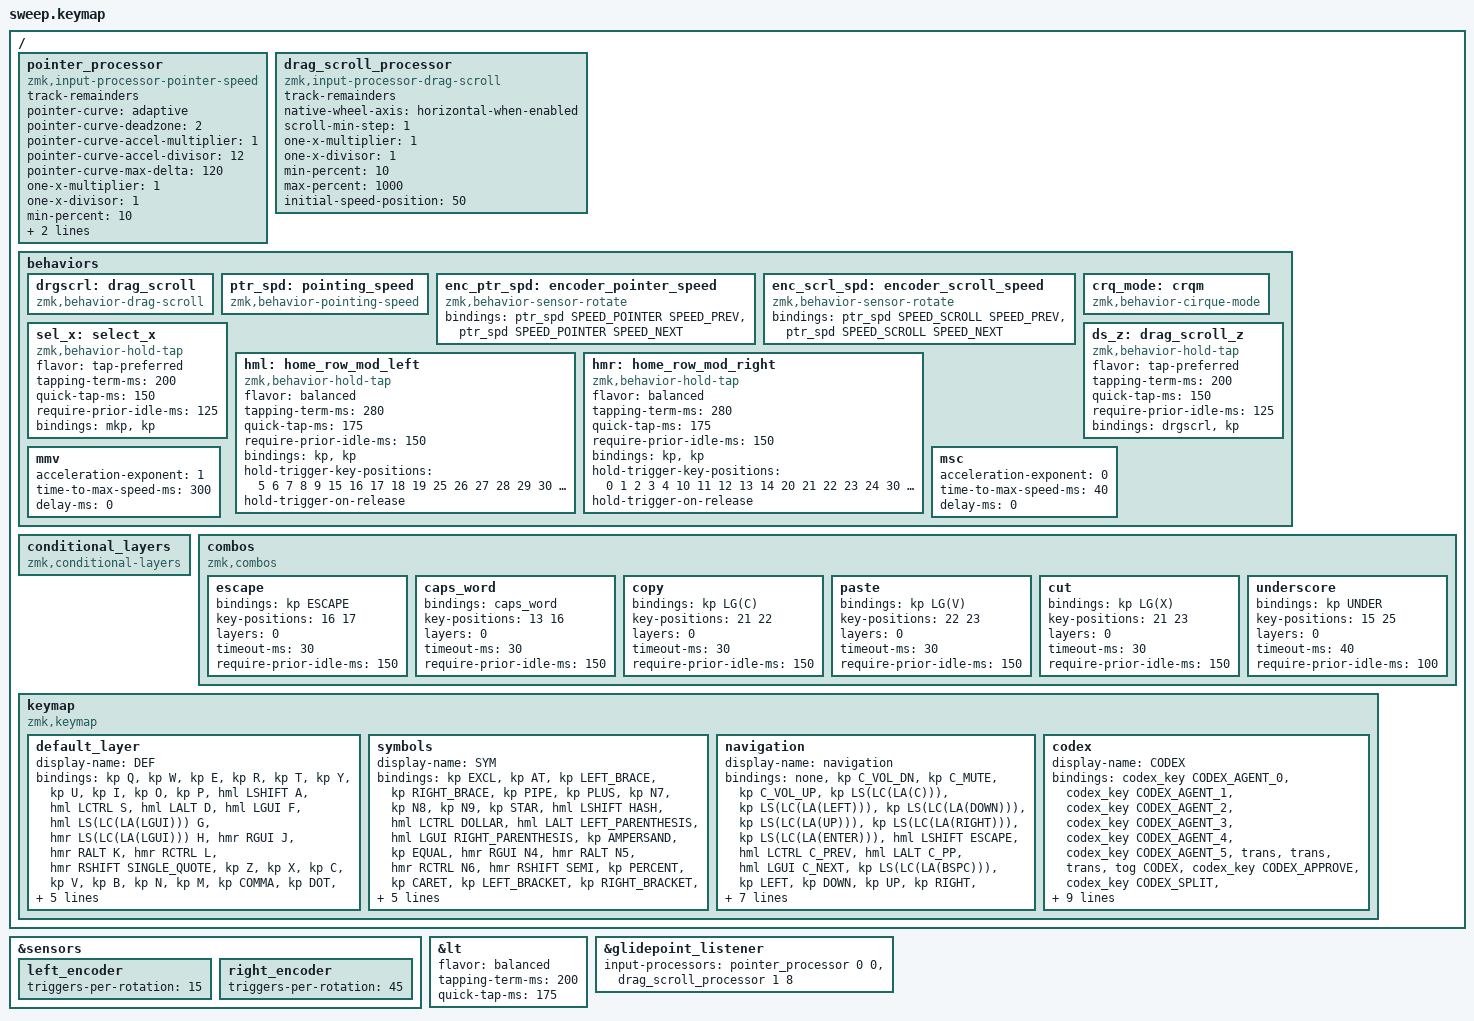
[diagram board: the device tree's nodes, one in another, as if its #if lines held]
// Copyright (c) 2022 The ZMK Contributors
// SPDX-License-Identifier: MIT
// #include <dt-bindings/zmk/rgb.h>

#define ZMK_POINTING_DEFAULT_MOVE_VAL 2500// 600
#define ZMK_POINTING_DEFAULT_SCRL_VAL 20// 10

#include <behaviors.dtsi>
#include <dt-bindings/zmk/keys.h>
#include <dt-bindings/zmk/pointing.h>

#if defined(NXTKB_CODEX_MICRO)
#include <dt-bindings/nxtkb/codex.h>
#include <behaviors/codex_key.dtsi>
#endif

#include "behaviors/character_map.dtsi"
#include "behaviors/report.dtsi"

#define MAC 0
#define WIN 1
#define RIG 2
#define LEF 3
#define TRI 4
#define MOUSE 5
#define CODEX 3
#define SPEED_POINTER 0
#define SPEED_SCROLL 1
#define SPEED_PREV 0
#define SPEED_NEXT 1
#define SPEED_RESET 2
#define SPEED_FINE_PREV 3
#define SPEED_FINE_NEXT 4
#define CIRQUE_MODE_RELATIVE 0
#define CIRQUE_MODE_ABSOLUTE 1
#define CIRQUE_MODE_TOGGLE 2

&sensors {
    left_encoder { triggers-per-rotation = <15>; };

    right_encoder { triggers-per-rotation = <45>; };
};

&lt {
    flavor = "balanced";
    tapping-term-ms = <200>;
    quick-tap-ms = <175>;
};

&glidepoint_listener { input-processors = <&pointer_processor 0 0 &drag_scroll_processor 1 8>; };

/ {
    pointer_processor: pointer_processor {
        compatible = "zmk,input-processor-pointer-speed";
        #input-processor-cells = <2>;
        track-remainders;
        pointer-curve = "adaptive";
        pointer-curve-deadzone = <2>;
        pointer-curve-accel-multiplier = <1>;
        pointer-curve-accel-divisor = <12>;
        pointer-curve-max-delta = <120>;
        one-x-multiplier = <1>;
        one-x-divisor = <1>;
        min-percent = <10>;
        max-percent = <400>;
        initial-speed-position = <50>;
    };

    drag_scroll_processor: drag_scroll_processor {
        compatible = "zmk,input-processor-drag-scroll";
        #input-processor-cells = <2>;
        track-remainders;
        native-wheel-axis = "horizontal-when-enabled";
        scroll-min-step = <1>;
        one-x-multiplier = <1>;
        one-x-divisor = <1>;
        min-percent = <10>;
        max-percent = <1000>;
        initial-speed-position = <50>;
    };

    behaviors {
        drgscrl: drag_scroll {
            compatible = "zmk,behavior-drag-scroll";
            #binding-cells = <0>;
        };

        ptr_spd: pointing_speed {
            compatible = "zmk,behavior-pointing-speed";
            #binding-cells = <2>;
        };

        enc_ptr_spd: encoder_pointer_speed {
            compatible = "zmk,behavior-sensor-rotate";
            #sensor-binding-cells = <0>;
            bindings =
                <&ptr_spd SPEED_POINTER SPEED_PREV>,
                <&ptr_spd SPEED_POINTER SPEED_NEXT>;
        };

        enc_scrl_spd: encoder_scroll_speed {
            compatible = "zmk,behavior-sensor-rotate";
            #sensor-binding-cells = <0>;
            bindings =
                <&ptr_spd SPEED_SCROLL SPEED_PREV>,
                <&ptr_spd SPEED_SCROLL SPEED_NEXT>;
        };

        crq_mode: crqm {
            compatible = "zmk,behavior-cirque-mode";
            #binding-cells = <1>;
        };

        sel_x: select_x {
            compatible = "zmk,behavior-hold-tap";
            #binding-cells = <2>;
            flavor = "tap-preferred";
            tapping-term-ms = <200>;
            quick-tap-ms = <150>;
            require-prior-idle-ms = <125>;
            bindings = <&mkp>, <&kp>;
        };

        ds_z: drag_scroll_z {
            compatible = "zmk,behavior-hold-tap";
            #binding-cells = <2>;
            flavor = "tap-preferred";
            tapping-term-ms = <200>;
            quick-tap-ms = <150>;
            require-prior-idle-ms = <125>;
            bindings = <&drgscrl>, <&kp>;
        };

        // Timeless positional home row mods (urob-style): balanced +
        // require-prior-idle + cross-hand-only trigger positions.
        // Left: 0-4 10-14 20-24, right: 5-9 15-19 25-29, thumbs: 30-35.

        hml: home_row_mod_left {
            compatible = "zmk,behavior-hold-tap";
            #binding-cells = <2>;
            flavor = "balanced";
            tapping-term-ms = <280>;
            quick-tap-ms = <175>;
            require-prior-idle-ms = <150>;
            bindings = <&kp>, <&kp>;

            hold-trigger-key-positions = <5 6 7 8 9 15 16 17 18 19 25 26 27 28 29 30 31 32 33 34 35>;
            hold-trigger-on-release;
        };

        hmr: home_row_mod_right {
            compatible = "zmk,behavior-hold-tap";
            #binding-cells = <2>;
            flavor = "balanced";
            tapping-term-ms = <280>;
            quick-tap-ms = <175>;
            require-prior-idle-ms = <150>;
            bindings = <&kp>, <&kp>;

            hold-trigger-key-positions = <0 1 2 3 4 10 11 12 13 14 20 21 22 23 24 30 31 32 33 34 35>;
            hold-trigger-on-release;
        };

        mmv {
            acceleration-exponent = <1>;// 1
            time-to-max-speed-ms = <300>;// 40
            delay-ms = <0>;// 0
        };

        msc {
            acceleration-exponent = <0>;// 0
            time-to-max-speed-ms = <40>;// 500
            delay-ms = <0>;// 10
        };
    };

    conditional_layers { compatible = "zmk,conditional-layers"; };

    combos {
        compatible = "zmk,combos";

        escape {
            bindings = <&kp ESCAPE>;
            key-positions = <16 17>;        // J + K
            layers = <0>;
            timeout-ms = <30>;
            require-prior-idle-ms = <150>;
        };

        caps_word {
            bindings = <&caps_word>;
            key-positions = <13 16>;        // F + J
            layers = <0>;
            timeout-ms = <30>;
            require-prior-idle-ms = <150>;
        };

        copy {
            bindings = <&kp LG(C)>;
            key-positions = <21 22>;        // X + C
            layers = <0>;
            timeout-ms = <30>;
            require-prior-idle-ms = <150>;
        };

        paste {
            bindings = <&kp LG(V)>;
            key-positions = <22 23>;        // C + V
            layers = <0>;
            timeout-ms = <30>;
            require-prior-idle-ms = <150>;
        };

        cut {
            bindings = <&kp LG(X)>;
            key-positions = <21 23>;        // X + V
            layers = <0>;
            timeout-ms = <30>;
            require-prior-idle-ms = <150>;
        };

        underscore {
            bindings = <&kp UNDER>;
            key-positions = <15 25>;        // H + N
            layers = <0>;
            timeout-ms = <40>;
            require-prior-idle-ms = <100>;
        };
    };

    keymap {
        compatible = "zmk,keymap";

        default_layer {
            display-name = "DEF";
            bindings = <
&kp Q          &kp W         &kp E        &kp R                     &kp T                     &kp Y                     &kp U        &kp I        &kp O         &kp P
&hml LSHIFT A  &hml LCTRL S  &hml LALT D  &hml LGUI F               &hml LS(LC(LA(LGUI))) G   &hmr LS(LC(LA(LGUI))) H   &hmr RGUI J  &hmr RALT K  &hmr RCTRL L  &hmr RSHIFT SINGLE_QUOTE
&kp Z          &kp X         &kp C        &kp V                     &kp B                     &kp N                     &kp M        &kp COMMA    &kp DOT       &kp SLASH
                             &kp C_MUTE   &lt 1 BACKSPACE           &lt 2 TAB                 &lt 2 ENTER               &lt 1 SPACE  &studio_unlock
            >;

            sensor-bindings = <&inc_dec_kp C_VOL_DN C_VOL_UP &inc_dec_kp C_BRI_DEC C_BRI_UP>;
        };

        symbols {
            display-name = "SYM";
            bindings = <
&kp EXCL          &kp AT             &kp LEFT_BRACE              &kp RIGHT_BRACE              &kp PIPE       &kp PLUS   &kp N7       &kp N8       &kp N9        &kp STAR
&hml LSHIFT HASH  &hml LCTRL DOLLAR  &hml LALT LEFT_PARENTHESIS  &hml LGUI RIGHT_PARENTHESIS  &kp AMPERSAND  &kp EQUAL  &hmr RGUI N4  &hmr RALT N5  &hmr RCTRL N6  &hmr RSHIFT SEMI
&kp PERCENT       &kp CARET          &kp LEFT_BRACKET            &kp RIGHT_BRACKET            &kp TILDE      &kp MINUS  &kp N1       &kp N2       &kp N3        &kp SLASH
                                     &kp C_MUTE                  &kp BACKSLASH                &kp GRAVE      &kp SPACE  &kp N0       &studio_unlock
            >;

            sensor-bindings = <&inc_dec_kp C_VOL_DN C_VOL_UP &inc_dec_kp C_BRI_DEC C_BRI_UP>;
        };

        navigation {
            display-name = "navigation";
            bindings = <
&none               &kp C_VOL_DN       &kp C_MUTE        &kp C_VOL_UP      &kp LS(LC(LA(C)))     &kp LS(LC(LA(LEFT)))  &kp LS(LC(LA(DOWN)))  &kp LS(LC(LA(UP)))  &kp LS(LC(LA(RIGHT)))  &kp LS(LC(LA(ENTER)))
&hml LSHIFT ESCAPE  &hml LCTRL C_PREV  &hml LALT C_PP    &hml LGUI C_NEXT  &kp LS(LC(LA(BSPC)))  &kp LEFT              &kp DOWN              &kp UP              &kp RIGHT              &kp LC(LG(F))
&none               &kp K_CUT          &kp K_COPY        &kp K_PASTE       &none                 &kp HOME              &kp PG_DN             &kp PG_UP           &kp END                &kp LS(LC(LA(N)))
                                       &kp C_MUTE        &trans            &trans                &trans                &trans                &studio_unlock
            >;

            sensor-bindings = <&inc_dec_kp C_VOL_DN C_VOL_UP &inc_dec_kp C_BRI_DEC C_BRI_UP>;
        };

#if defined(NXTKB_CODEX_MICRO)
        codex {
            display-name = "CODEX";
            bindings = <
&codex_key CODEX_AGENT_0  &codex_key CODEX_AGENT_1  &codex_key CODEX_AGENT_2    &codex_key CODEX_AGENT_3  &codex_key CODEX_AGENT_4  &codex_key CODEX_AGENT_5  &trans  &trans  &trans  &tog CODEX
&codex_key CODEX_APPROVE  &codex_key CODEX_SPLIT    &codex_key CODEX_DECLINE    &codex_key CODEX_FAST     &trans                      &codex_key CODEX_MIC      &codex_key CODEX_SEND  &trans  &trans  &trans
&trans                     &trans                    &trans                       &trans                     &trans                      &trans                     &trans                  &trans  &trans  &trans
                                                      &trans                       &trans                     &trans                      &trans                     &trans                  &studio_unlock
            >;

            sensor-bindings = <&inc_dec_kp C_VOL_DN C_VOL_UP &inc_dec_kp C_BRI_DEC C_BRI_UP>;
        };
#endif
    };
};
